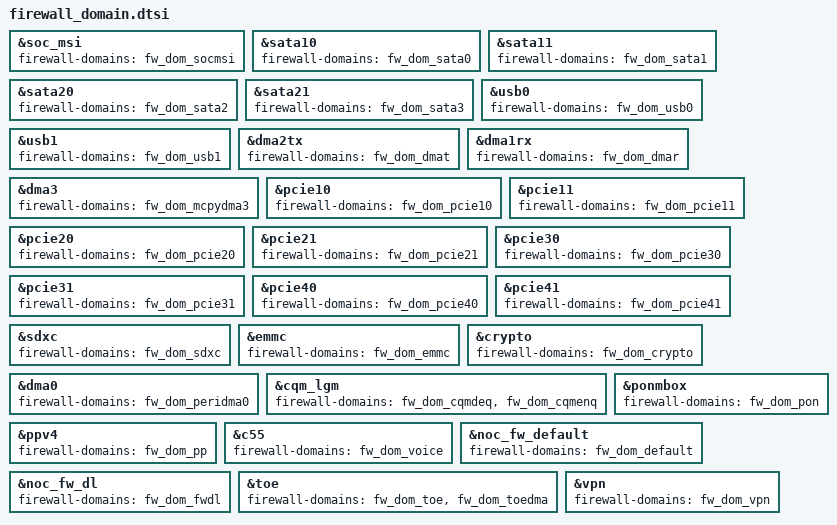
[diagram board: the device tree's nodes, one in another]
&soc_msi {
	firewall-domains = <&fw_dom_socmsi>;
};

#ifndef LGMC_SOC
&sata10 {
	firewall-domains = <&fw_dom_sata0>;
};

&sata11 {
	firewall-domains = <&fw_dom_sata1>;
};

&sata20 {
	firewall-domains = <&fw_dom_sata2>;
};

&sata21 {
	firewall-domains = <&fw_dom_sata3>;
};

&usb0 {
	firewall-domains = <&fw_dom_usb0>;
};
#endif

&usb1 {
	firewall-domains = <&fw_dom_usb1>;
};

&dma2tx {
	firewall-domains = <&fw_dom_dmat>;
};

&dma1rx {
	firewall-domains = <&fw_dom_dmar>;
};

&dma3 {
	firewall-domains = <&fw_dom_mcpydma3>;
};

&pcie10 {
	firewall-domains = <&fw_dom_pcie10>;
};

&pcie11 {
	firewall-domains = <&fw_dom_pcie11>;
};

&pcie20 {
	firewall-domains = <&fw_dom_pcie20>;
};

&pcie21 {
	firewall-domains = <&fw_dom_pcie21>;
};

&pcie30 {
	firewall-domains = <&fw_dom_pcie30>;
};

&pcie31 {
	firewall-domains = <&fw_dom_pcie31>;
};

&pcie40 {
	firewall-domains = <&fw_dom_pcie40>;
};

&pcie41 {
	firewall-domains = <&fw_dom_pcie41>;
};

&sdxc {
	firewall-domains = <&fw_dom_sdxc>;
};

&emmc {
	firewall-domains = <&fw_dom_emmc>;
};

&crypto {
	firewall-domains = <&fw_dom_crypto>;
};

&dma0 {
	firewall-domains = <&fw_dom_peridma0>;
};

&cqm_lgm {
	firewall-domains = <&fw_dom_cqmdeq &fw_dom_cqmenq>;
};

&ponmbox {
	firewall-domains=<&fw_dom_pon>;
};

&ppv4 {
	firewall-domains = <&fw_dom_pp>;
};

&c55 {
	firewall-domains = <&fw_dom_voice>;
};

&noc_fw_default {
	firewall-domains = <&fw_dom_default>;
};

&noc_fw_dl {
	firewall-domains = <&fw_dom_fwdl>;
};

&toe {
	firewall-domains = <&fw_dom_toe &fw_dom_toedma>;
};

&vpn {
	firewall-domains = <&fw_dom_vpn>;
};
